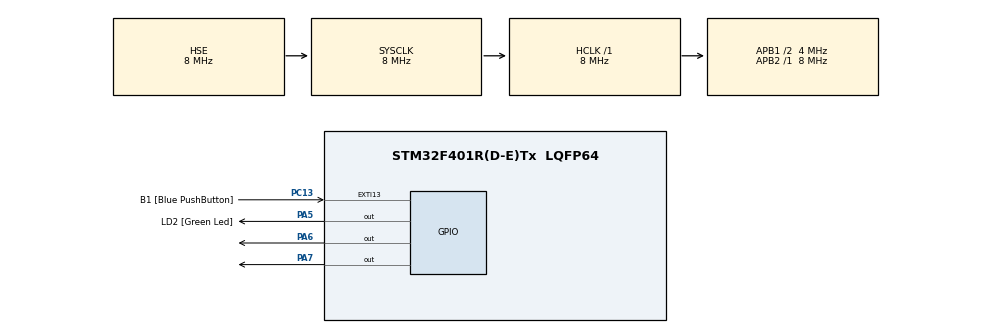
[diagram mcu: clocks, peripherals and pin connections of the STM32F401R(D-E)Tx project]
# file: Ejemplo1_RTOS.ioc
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FREERTOS.Tasks01=defaultTask,0,128,StartDefaultTask,Default,NULL,Dynamic,NULL,NULL;vTarea1,0,128,Task1,Default,NULL,Dynamic,NULL,NULL;vTarea2,0,128,Task2,Default,NULL,Dynamic,NULL,NULL
Mcu.Family=STM32F4
Mcu.Name=STM32F401R(D-E)Tx
Mcu.Package=LQFP64
NVIC.PriorityGroup=NVIC_PRIORITYGROUP_4
NVIC.TIM1_UP_TIM10_IRQn=true\:15\:0\:false\:false\:true\:false\:false\:true\:true
NVIC.TimeBase=TIM1_UP_TIM10_IRQn
NVIC.TimeBaseIP=TIM1
PA13.Mode=Serial_Wire
PA13.Signal=SYS_JTMS-SWDIO
PA14.Mode=Serial_Wire
PA14.Signal=SYS_JTCK-SWCLK
PA5.GPIO_Label=LD2 [Green Led]
PA5.GPIO_Mode=GPIO_MODE_OUTPUT_PP
PA5.GPIO_PuPd=GPIO_NOPULL
PA5.GPIO_Speed=GPIO_SPEED_FREQ_LOW
PA5.Signal=GPIO_Output
PA6.Signal=GPIO_Output
PA7.Signal=GPIO_Output
PC13-ANTI_TAMP.GPIO_Label=B1 [Blue PushButton]
PC13-ANTI_TAMP.GPIO_ModeDefaultEXTI=GPIO_MODE_IT_FALLING
PC13-ANTI_TAMP.GPIO_PuPd=GPIO_NOPULL
PC13-ANTI_TAMP.Signal=GPXTI13
PH0\ -\ OSC_IN.Mode=HSE-External-Clock-Source
PH0\ -\ OSC_IN.Signal=RCC_OSC_IN
PH1\ -\ OSC_OUT.Mode=HSE-External-Clock-Source
PH1\ -\ OSC_OUT.Signal=RCC_OSC_OUT
ProjectManager.HeapSize=0x200
ProjectManager.StackSize=0x400
ProjectManager.TargetToolchain=STM32CubeIDE
RCC.48MHZClocksFreq_Value=24000000
RCC.AHBFreq_Value=8000000
RCC.APB1CLKDivider=RCC_HCLK_DIV2
RCC.APB1Freq_Value=4000000
RCC.APB1TimFreq_Value=8000000
RCC.APB2Freq_Value=8000000
RCC.APB2TimFreq_Value=8000000
RCC.CortexFreq_Value=8000000
RCC.HCLKFreq_Value=8000000
RCC.HSE_VALUE=8000000
RCC.HSI_VALUE=16000000
RCC.LSE_VALUE=32768
RCC.PLLM=4
RCC.PLLN=84
RCC.PLLQ=7
RCC.PLLSourceVirtual=RCC_PLLSOURCE_HSE
RCC.SYSCLKFreq_VALUE=8000000
RCC.SYSCLKSource=RCC_SYSCLKSOURCE_HSE
RCC.VCOOutputFreq_Value=168000000
VP_FREERTOS_VS_CMSIS_V1.Mode=CMSIS_V1
VP_SYS_VS_tim1.Mode=TIM1
board=NUCLEO-F401RE

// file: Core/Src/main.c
/* USER CODE BEGIN Header */
/**
  ******************************************************************************
  * @file           : main.c
  * @brief          : Main program body
  ******************************************************************************
  * @attention
  *
  * Copyright (c) 2023 STMicroelectronics.
  * All rights reserved.
  *
  * This software is licensed under terms that can be found in the LICENSE file
  * in the root directory of this software component.
  * If no LICENSE file comes with this software, it is provided AS-IS.
  *
  ******************************************************************************
  */
/* USER CODE END Header */
#include "main.h"
#include "cmsis_os.h"

osThreadId defaultTaskHandle;
osThreadId vTarea1Handle;
osThreadId vTarea2Handle;

void SystemClock_Config(void);
static void MX_GPIO_Init(void);
void StartDefaultTask(void const * argument);
void Task1(void const * argument);
void Task2(void const * argument);

int main(void)
{

  /* MCU Configuration--------------------------------------------------------*/

  /* Reset of all peripherals, Initializes the Flash interface and the Systick. */
  HAL_Init();

  /* Configure the system clock */
  SystemClock_Config();

  /* Initialize all configured peripherals */
  MX_GPIO_Init();

  /* Create the thread(s) */
  /* definition and creation of defaultTask */
  osThreadDef(defaultTask, StartDefaultTask, osPriorityNormal, 0, 128);
  defaultTaskHandle = osThreadCreate(osThread(defaultTask), NULL);

  /* definition and creation of vTarea1 */
  osThreadDef(vTarea1, Task1, osPriorityNormal, 0, 128);
  vTarea1Handle = osThreadCreate(osThread(vTarea1), NULL);

  /* definition and creation of vTarea2 */
  osThreadDef(vTarea2, Task2, osPriorityNormal, 0, 128);
  vTarea2Handle = osThreadCreate(osThread(vTarea2), NULL);

  /* Start scheduler */
  osKernelStart();

  /* We should never get here as control is now taken by the scheduler */
  /* Infinite loop */
  while (1)
  {

  }
}

void SystemClock_Config(void)
{
  RCC_OscInitTypeDef RCC_OscInitStruct = {0};
  RCC_ClkInitTypeDef RCC_ClkInitStruct = {0};

  /** Configure the main internal regulator output voltage
  */
  __HAL_RCC_PWR_CLK_ENABLE();
  __HAL_PWR_VOLTAGESCALING_CONFIG(PWR_REGULATOR_VOLTAGE_SCALE2);

  /** Initializes the RCC Oscillators according to the specified parameters
  * in the RCC_OscInitTypeDef structure.
  */
  RCC_OscInitStruct.OscillatorType = RCC_OSCILLATORTYPE_HSE;
  RCC_OscInitStruct.HSEState = RCC_HSE_BYPASS;
  RCC_OscInitStruct.PLL.PLLState = RCC_PLL_NONE;
  if (HAL_RCC_OscConfig(&RCC_OscInitStruct) != HAL_OK)
  {
    Error_Handler();
  }

  /** Initializes the CPU, AHB and APB buses clocks
  */
  RCC_ClkInitStruct.ClockType = RCC_CLOCKTYPE_HCLK|RCC_CLOCKTYPE_SYSCLK
                              |RCC_CLOCKTYPE_PCLK1|RCC_CLOCKTYPE_PCLK2;
  RCC_ClkInitStruct.SYSCLKSource = RCC_SYSCLKSOURCE_HSE;
  RCC_ClkInitStruct.AHBCLKDivider = RCC_SYSCLK_DIV1;
  RCC_ClkInitStruct.APB1CLKDivider = RCC_HCLK_DIV2;
  RCC_ClkInitStruct.APB2CLKDivider = RCC_HCLK_DIV1;

  if (HAL_RCC_ClockConfig(&RCC_ClkInitStruct, FLASH_LATENCY_0) != HAL_OK)
  {
    Error_Handler();
  }
}

static void MX_GPIO_Init(void)
{
  GPIO_InitTypeDef GPIO_InitStruct = {0};

  /* GPIO Ports Clock Enable */
  __HAL_RCC_GPIOC_CLK_ENABLE();
  __HAL_RCC_GPIOH_CLK_ENABLE();
  __HAL_RCC_GPIOA_CLK_ENABLE();

  /*Configure GPIO pin Output Level */
  HAL_GPIO_WritePin(GPIOA, LD2_Pin|GPIO_PIN_6|GPIO_PIN_7, GPIO_PIN_RESET);

  /*Configure GPIO pin : B1_Pin */
  GPIO_InitStruct.Pin = B1_Pin;
  GPIO_InitStruct.Mode = GPIO_MODE_IT_FALLING;
  GPIO_InitStruct.Pull = GPIO_NOPULL;
  HAL_GPIO_Init(B1_GPIO_Port, &GPIO_InitStruct);

  /*Configure GPIO pins : LD2_Pin PA6 PA7 */
  GPIO_InitStruct.Pin = LD2_Pin|GPIO_PIN_6|GPIO_PIN_7;
  GPIO_InitStruct.Mode = GPIO_MODE_OUTPUT_PP;
  GPIO_InitStruct.Pull = GPIO_NOPULL;
  GPIO_InitStruct.Speed = GPIO_SPEED_FREQ_LOW;
  HAL_GPIO_Init(GPIOA, &GPIO_InitStruct);

}

void StartDefaultTask(void const * argument)
{
  /* USER CODE BEGIN 5 */
  /* Infinite loop */
  for(;;)
  {
	  HAL_GPIO_TogglePin(GPIOA, GPIO_PIN_5);

    osDelay(700);
  }
  /* USER CODE END 5 */
}

void Task1(void const * argument)
{
  /* USER CODE BEGIN Task1 */
  /* Infinite loop */
  for(;;)
  {

	  HAL_GPIO_TogglePin(GPIOA, GPIO_PIN_6);

    osDelay(275);
  }
  /* USER CODE END Task1 */
}

void Task2(void const * argument)
{
  /* USER CODE BEGIN Task2 */
  /* Infinite loop */
  for(;;)
  {

	  HAL_GPIO_TogglePin(GPIOA, GPIO_PIN_7);
    osDelay(500);
  }
  /* USER CODE END Task2 */
}

void HAL_TIM_PeriodElapsedCallback(TIM_HandleTypeDef *htim)
{
  if (htim->Instance == TIM1) {
    HAL_IncTick();
  }
}

void Error_Handler(void)
{
  __disable_irq();
  while (1)
  {
  }
}
